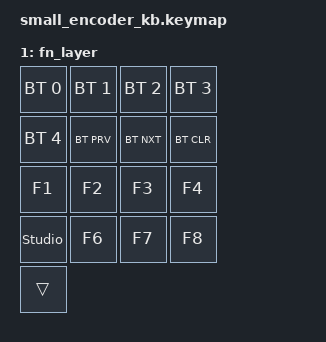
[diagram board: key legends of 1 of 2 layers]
#include <behaviors.dtsi>
#include <dt-bindings/zmk/keys.h>
#include <dt-bindings/zmk/bt.h>       // 蓝牙行为
#include <dt-bindings/zmk/studio.h>   // Studio 解锁

/ {
    keymap {
        compatible = "zmk,keymap";

        default_layer {
            bindings = <
                &kp ESC    &kp Q     &kp W     &kp E
                &kp TAB    &kp A     &kp S     &kp D
                &kp LSHFT  &kp Z     &kp X     &kp C
                &kp LCTRL  &kp LGUI
                &mo 1                                     // 按住旋钮激活 Fn 层
            >;

            sensor-bindings = <&inc_dec_kp C_VOL_UP C_VOL_DN>;
        };

        fn_layer {
            bindings = <
                &bt BT_SEL 0   &bt BT_SEL 1   &bt BT_SEL 2   &bt BT_SEL 3   // 行0：切换设备0~3
                &bt BT_SEL 4   &bt BT_PRV      &bt BT_NXT     &bt BT_CLR     // 行1：设备4、上一个、下一个、清除当前配对
                &kp F1         &kp F2         &kp F3         &kp F4         // 行2：F1~F4
                &studio_unlock &kp F6         &kp F7         &kp F8         // 行3：左下键解锁 Studio，其余 F6~F8
                &trans                                                        // 行4：旋钮位置完全透明
            >;

            sensor-bindings = <&inc_dec_kp PG_UP PG_DN>;
        };
    };
};
